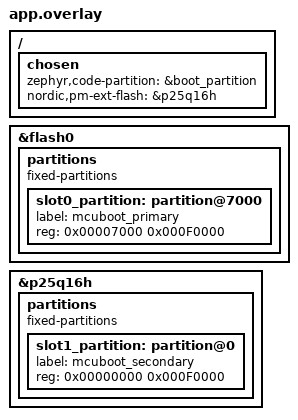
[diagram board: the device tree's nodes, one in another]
/ {
	chosen {
		zephyr,code-partition = &boot_partition;
		nordic,pm-ext-flash = &p25q16h;
	};
};

&flash0 {
	partitions {
		compatible = "fixed-partitions";
		#address-cells = <1>;
		#size-cells = <1>;

		slot0_partition: partition@7000 {
			label = "mcuboot_primary";
			reg = <0x00007000 0x000F0000>;
		};
	};
};

&p25q16h {
	partitions {
		compatible = "fixed-partitions";
		#address-cells = <1>;
		#size-cells = <1>;

		slot1_partition: partition@0 {
			label = "mcuboot_secondary";
			reg = <0x00000000 0x000F0000>;
		};
	};
};
